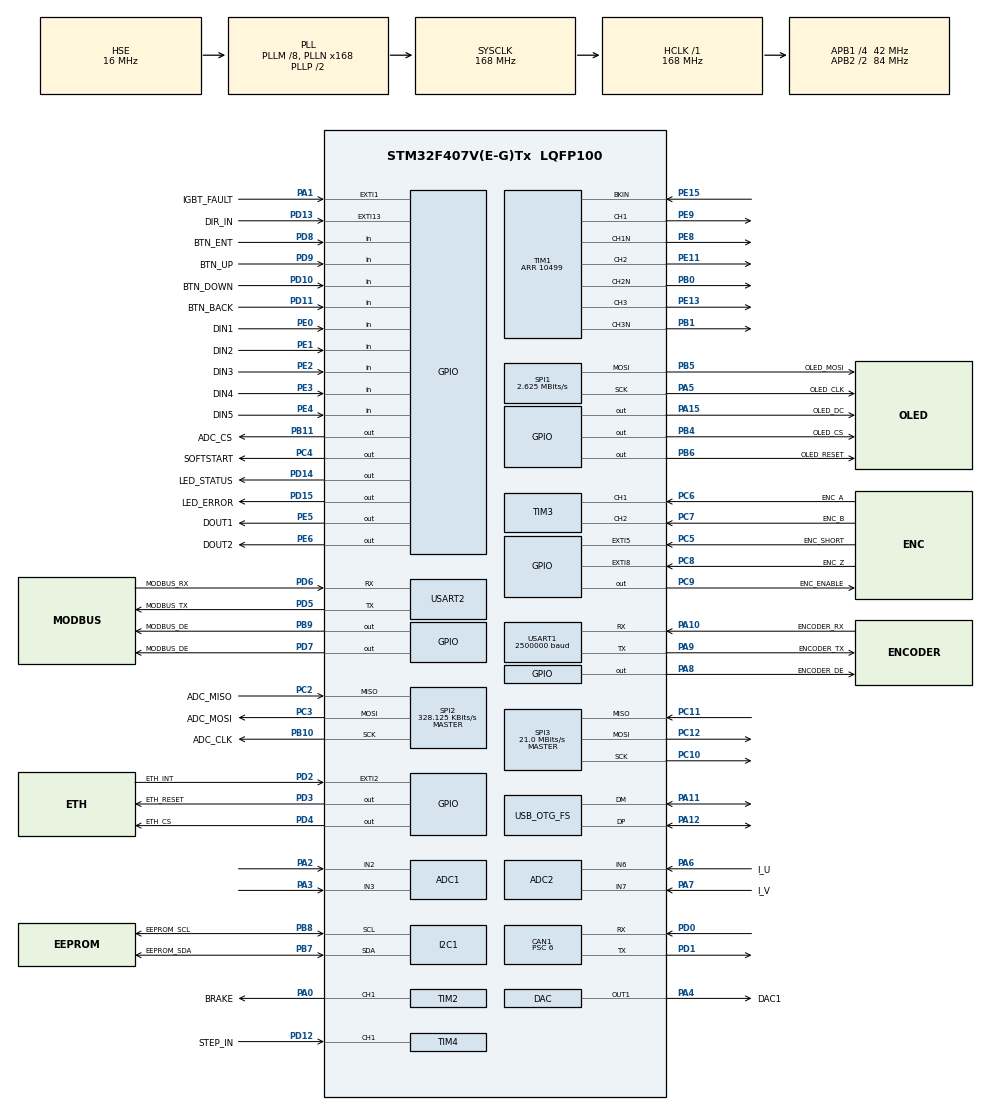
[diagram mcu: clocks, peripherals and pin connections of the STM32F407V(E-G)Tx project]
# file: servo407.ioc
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ADC1.Channel-1\#ChannelRegularConversion=ADC_CHANNEL_2
ADC1.Channel-2\#ChannelRegularConversion=ADC_CHANNEL_3
ADC1.ContinuousConvMode=ENABLE
ADC1.DMAContinuousRequests=ENABLE
ADC1.NbrOfConversion=2
ADC1.NbrOfConversionFlag=1
ADC1.Rank-1\#ChannelRegularConversion=1
ADC1.Rank-2\#ChannelRegularConversion=2
ADC1.SamplingTime-1\#ChannelRegularConversion=ADC_SAMPLETIME_56CYCLES
ADC1.SamplingTime-2\#ChannelRegularConversion=ADC_SAMPLETIME_56CYCLES
ADC1.ScanConvMode=ENABLE
ADC1.master=1
ADC2.Channel-2\#ChannelRegularConversion=ADC_CHANNEL_6
ADC2.Channel-3\#ChannelRegularConversion=ADC_CHANNEL_7
ADC2.ContinuousConvMode=ENABLE
ADC2.DMAContinuousRequests=ENABLE
ADC2.NbrOfConversion=2
ADC2.NbrOfConversionFlag=1
ADC2.Rank-2\#ChannelRegularConversion=1
ADC2.Rank-3\#ChannelRegularConversion=2
ADC2.SamplingTime-2\#ChannelRegularConversion=ADC_SAMPLETIME_15CYCLES
ADC2.SamplingTime-3\#ChannelRegularConversion=ADC_SAMPLETIME_15CYCLES
ADC2.ScanConvMode=ENABLE
CAN1.ABOM=ENABLE
CAN1.BS1=CAN_BS1_11TQ
CAN1.BS2=CAN_BS2_2TQ
CAN1.CalculateBaudRate=500000
CAN1.CalculateTimeBit=2000
CAN1.CalculateTimeQuantum=142.85714285714286
CAN1.NART=ENABLE
CAN1.Prescaler=6
Dma.ADC1.0.Direction=DMA_PERIPH_TO_MEMORY
Dma.ADC1.0.FIFOMode=DMA_FIFOMODE_DISABLE
Dma.ADC1.0.Instance=DMA2_Stream0
Dma.ADC1.0.MemDataAlignment=DMA_MDATAALIGN_HALFWORD
Dma.ADC1.0.MemInc=DMA_MINC_ENABLE
Dma.ADC1.0.Mode=DMA_CIRCULAR
Dma.ADC1.0.PeriphDataAlignment=DMA_PDATAALIGN_HALFWORD
Dma.ADC1.0.PeriphInc=DMA_PINC_DISABLE
Dma.ADC1.0.Priority=DMA_PRIORITY_LOW
Dma.ADC2.1.Direction=DMA_PERIPH_TO_MEMORY
Dma.ADC2.1.FIFOMode=DMA_FIFOMODE_DISABLE
Dma.ADC2.1.Instance=DMA2_Stream2
Dma.ADC2.1.MemDataAlignment=DMA_MDATAALIGN_HALFWORD
Dma.ADC2.1.MemInc=DMA_MINC_ENABLE
Dma.ADC2.1.Mode=DMA_CIRCULAR
Dma.ADC2.1.PeriphDataAlignment=DMA_PDATAALIGN_HALFWORD
Dma.ADC2.1.PeriphInc=DMA_PINC_DISABLE
Dma.ADC2.1.Priority=DMA_PRIORITY_LOW
Dma.I2C1_RX.7.Direction=DMA_PERIPH_TO_MEMORY
Dma.I2C1_RX.7.FIFOMode=DMA_FIFOMODE_DISABLE
Dma.I2C1_RX.7.Instance=DMA1_Stream0
Dma.I2C1_RX.7.MemDataAlignment=DMA_MDATAALIGN_BYTE
Dma.I2C1_RX.7.MemInc=DMA_MINC_ENABLE
Dma.I2C1_RX.7.Mode=DMA_NORMAL
Dma.I2C1_RX.7.PeriphDataAlignment=DMA_PDATAALIGN_BYTE
Dma.I2C1_RX.7.PeriphInc=DMA_PINC_DISABLE
Dma.I2C1_RX.7.Priority=DMA_PRIORITY_LOW
Dma.I2C1_TX.8.Direction=DMA_MEMORY_TO_PERIPH
Dma.I2C1_TX.8.FIFOMode=DMA_FIFOMODE_DISABLE
Dma.I2C1_TX.8.Instance=DMA1_Stream6
Dma.I2C1_TX.8.MemDataAlignment=DMA_MDATAALIGN_BYTE
Dma.I2C1_TX.8.MemInc=DMA_MINC_ENABLE
Dma.I2C1_TX.8.Mode=DMA_NORMAL
Dma.I2C1_TX.8.PeriphDataAlignment=DMA_PDATAALIGN_BYTE
Dma.I2C1_TX.8.PeriphInc=DMA_PINC_DISABLE
Dma.I2C1_TX.8.Priority=DMA_PRIORITY_LOW
Dma.Request0=ADC1
Dma.Request1=ADC2
Dma.Request2=SPI2_TX
Dma.Request3=SPI2_RX
Dma.Request4=USART1_RX
Dma.Request5=USART1_TX
Dma.Request6=SPI1_TX
Dma.Request7=I2C1_RX
Dma.Request8=I2C1_TX
Dma.SPI1_TX.6.Direction=DMA_MEMORY_TO_PERIPH
Dma.SPI1_TX.6.FIFOMode=DMA_FIFOMODE_DISABLE
Dma.SPI1_TX.6.Instance=DMA2_Stream3
Dma.SPI1_TX.6.MemDataAlignment=DMA_MDATAALIGN_BYTE
Dma.SPI1_TX.6.MemInc=DMA_MINC_ENABLE
Dma.SPI1_TX.6.Mode=DMA_NORMAL
Dma.SPI1_TX.6.PeriphDataAlignment=DMA_PDATAALIGN_BYTE
Dma.SPI1_TX.6.PeriphInc=DMA_PINC_DISABLE
Dma.SPI1_TX.6.Priority=DMA_PRIORITY_LOW
Dma.SPI2_RX.3.Direction=DMA_PERIPH_TO_MEMORY
Dma.SPI2_RX.3.FIFOMode=DMA_FIFOMODE_DISABLE
Dma.SPI2_RX.3.Instance=DMA1_Stream3
Dma.SPI2_RX.3.MemDataAlignment=DMA_MDATAALIGN_BYTE
Dma.SPI2_RX.3.MemInc=DMA_MINC_ENABLE
Dma.SPI2_RX.3.Mode=DMA_NORMAL
Dma.SPI2_RX.3.PeriphDataAlignment=DMA_PDATAALIGN_BYTE
Dma.SPI2_RX.3.PeriphInc=DMA_PINC_DISABLE
Dma.SPI2_RX.3.Priority=DMA_PRIORITY_LOW
Dma.SPI2_TX.2.Direction=DMA_MEMORY_TO_PERIPH
Dma.SPI2_TX.2.FIFOMode=DMA_FIFOMODE_DISABLE
Dma.SPI2_TX.2.Instance=DMA1_Stream4
Dma.SPI2_TX.2.MemDataAlignment=DMA_MDATAALIGN_BYTE
Dma.SPI2_TX.2.MemInc=DMA_MINC_ENABLE
Dma.SPI2_TX.2.Mode=DMA_NORMAL
Dma.SPI2_TX.2.PeriphDataAlignment=DMA_PDATAALIGN_BYTE
Dma.SPI2_TX.2.PeriphInc=DMA_PINC_DISABLE
Dma.SPI2_TX.2.Priority=DMA_PRIORITY_LOW
Dma.USART1_RX.4.Direction=DMA_PERIPH_TO_MEMORY
Dma.USART1_RX.4.FIFOMode=DMA_FIFOMODE_DISABLE
Dma.USART1_RX.4.Instance=DMA2_Stream5
Dma.USART1_RX.4.MemDataAlignment=DMA_MDATAALIGN_BYTE
Dma.USART1_RX.4.MemInc=DMA_MINC_ENABLE
Dma.USART1_RX.4.Mode=DMA_NORMAL
Dma.USART1_RX.4.PeriphDataAlignment=DMA_PDATAALIGN_BYTE
Dma.USART1_RX.4.PeriphInc=DMA_PINC_DISABLE
Dma.USART1_RX.4.Priority=DMA_PRIORITY_LOW
Dma.USART1_TX.5.Direction=DMA_MEMORY_TO_PERIPH
Dma.USART1_TX.5.FIFOMode=DMA_FIFOMODE_DISABLE
Dma.USART1_TX.5.Instance=DMA2_Stream7
Dma.USART1_TX.5.MemDataAlignment=DMA_MDATAALIGN_BYTE
Dma.USART1_TX.5.MemInc=DMA_MINC_ENABLE
Dma.USART1_TX.5.Mode=DMA_NORMAL
Dma.USART1_TX.5.PeriphDataAlignment=DMA_PDATAALIGN_BYTE
Dma.USART1_TX.5.PeriphInc=DMA_PINC_DISABLE
Dma.USART1_TX.5.Priority=DMA_PRIORITY_LOW
FREERTOS.Tasks01=defaultTask,32,256,StartDefaultTask,Default,NULL,Dynamic,NULL,NULL;taskModbusUSB,24,1024,StartTaskModbusUSB,Default,NULL,Dynamic,NULL,NULL;uiTask,16,1024,uiTaskStart,Default,NULL,Static,uiTaskBuffer,uiTaskControlBlock;canopen,25,2048,canopen_task,Default,NULL,Static,canopenBuffer,canopenControlBlock
FREERTOS.Timers01=timerSoftstart,timerSoftstartCallback,osTimerOnce,Default,NULL,Static,timerSoftstartControlBlock;LEDTimer,LEDTimerCallback,osTimerPeriodic,Default,NULL,Static,LEDTimerControlBlock
FREERTOS.configCHECK_FOR_STACK_OVERFLOW=2
FREERTOS.configENABLE_FPU=1
FREERTOS.configGENERATE_RUN_TIME_STATS=1
FREERTOS.configTIMER_TASK_PRIORITY=32
FREERTOS.configTOTAL_HEAP_SIZE=16384
FREERTOS.configUSE_MALLOC_FAILED_HOOK=1
FREERTOS.configUSE_NEWLIB_REENTRANT=1
I2C1.I2C_Mode=I2C_Fast
Mcu.Family=STM32F4
Mcu.Name=STM32F407V(E-G)Tx
Mcu.Package=LQFP100
NVIC.CAN1_RX0_IRQn=true\:7\:0\:true\:false\:true\:true\:true\:true\:true
NVIC.CAN1_RX1_IRQn=true\:7\:0\:true\:false\:true\:true\:true\:true\:true
NVIC.CAN1_TX_IRQn=true\:7\:0\:true\:false\:true\:true\:true\:true\:true
NVIC.DMA1_Stream0_IRQn=true\:7\:0\:true\:false\:true\:true\:false\:true\:true
NVIC.DMA1_Stream3_IRQn=true\:7\:0\:true\:false\:true\:true\:false\:true\:true
NVIC.DMA1_Stream4_IRQn=true\:7\:0\:true\:false\:true\:true\:false\:true\:true
NVIC.DMA1_Stream6_IRQn=true\:7\:0\:true\:false\:true\:true\:false\:true\:true
NVIC.DMA2_Stream0_IRQn=true\:7\:0\:true\:false\:true\:true\:false\:true\:true
NVIC.DMA2_Stream2_IRQn=true\:7\:0\:true\:false\:true\:true\:false\:true\:true
NVIC.DMA2_Stream3_IRQn=true\:7\:0\:true\:false\:true\:true\:false\:true\:true
NVIC.DMA2_Stream5_IRQn=true\:7\:0\:true\:false\:true\:true\:false\:true\:true
NVIC.DMA2_Stream7_IRQn=true\:7\:0\:true\:false\:true\:true\:false\:true\:true
NVIC.EXTI15_10_IRQn=true\:5\:0\:true\:false\:true\:true\:true\:true\:true
NVIC.EXTI1_IRQn=true\:5\:0\:true\:false\:true\:true\:true\:true\:true
NVIC.EXTI9_5_IRQn=true\:5\:0\:true\:false\:true\:true\:true\:true\:true
NVIC.OTG_FS_IRQn=true\:7\:0\:true\:false\:true\:true\:false\:true\:true
NVIC.PriorityGroup=NVIC_PRIORITYGROUP_4
NVIC.TIM1_TRG_COM_TIM11_IRQn=true\:15\:0\:false\:false\:true\:false\:false\:true\:true
NVIC.TIM5_IRQn=true\:6\:0\:true\:false\:true\:true\:true\:true\:true
NVIC.TIM6_DAC_IRQn=true\:7\:0\:true\:false\:true\:true\:true\:true\:true
NVIC.TIM7_IRQn=true\:5\:0\:false\:false\:true\:true\:true\:true\:true
NVIC.TimeBase=TIM1_TRG_COM_TIM11_IRQn
NVIC.TimeBaseIP=TIM11
PA0-WKUP.GPIO_Label=BRAKE
PA0-WKUP.Signal=S_TIM2_CH1_ETR
PA1.GPIO_Label=IGBT_FAULT
PA1.Signal=GPXTI1
PA10.GPIO_Label=ENCODER_RX
PA10.Mode=Asynchronous
PA10.Signal=USART1_RX
PA11.Mode=Device_Only
PA11.Signal=USB_OTG_FS_DM
PA12.Mode=Device_Only
PA12.Signal=USB_OTG_FS_DP
PA13.Mode=Trace_Asynchronous_SW
PA13.Signal=SYS_JTMS-SWDIO
PA14.Mode=Trace_Asynchronous_SW
PA14.Signal=SYS_JTCK-SWCLK
PA15.GPIO_Label=OLED_DC
PA15.Signal=GPIO_Output
PA2.Signal=ADCx_IN2
PA3.Signal=ADCx_IN3
PA4.GPIO_Label=DAC1
PA4.Signal=COMP_DAC1_group
PA5.GPIO_Label=OLED_CLK
PA5.Mode=TX_Only_Simplex_Unidirect_Master
PA5.Signal=SPI1_SCK
PA6.GPIO_Label=I_U
PA6.Signal=ADCx_IN6
PA7.GPIO_Label=I_V
PA7.Signal=ADCx_IN7
PA8.GPIO_Label=ENCODER_DE
PA8.PinState=GPIO_PIN_RESET
PA8.Signal=GPIO_Output
PA9.GPIO_Label=ENCODER_TX
PA9.Mode=Asynchronous
PA9.Signal=USART1_TX
PB0.GPIO_ModeDefaultPP=GPIO_MODE_AF_PP
PB0.GPIO_PuPd=GPIO_NOPULL
PB0.GPIO_Speed=GPIO_SPEED_FREQ_LOW
PB0.Mode=PWM Generation2 CH2 CH2N
PB0.Signal=TIM1_CH2N
PB1.GPIO_ModeDefaultPP=GPIO_MODE_AF_PP
PB1.GPIO_PuPd=GPIO_NOPULL
PB1.GPIO_Speed=GPIO_SPEED_FREQ_LOW
PB1.Mode=PWM Generation3 CH3 CH3N
PB1.Signal=TIM1_CH3N
PB10.GPIO_Label=ADC_CLK
PB10.Mode=Full_Duplex_Master
PB10.Signal=SPI2_SCK
PB11.GPIO_Label=ADC_CS
PB11.PinState=GPIO_PIN_SET
PB11.Signal=GPIO_Output
PB3.Mode=Trace_Asynchronous_SW
PB3.Signal=SYS_JTDO-SWO
PB4.GPIO_Label=OLED_CS
PB4.PinState=GPIO_PIN_SET
PB4.Signal=GPIO_Output
PB5.GPIO_Label=OLED_MOSI
PB5.Mode=TX_Only_Simplex_Unidirect_Master
PB5.Signal=SPI1_MOSI
PB6.GPIO_Label=OLED_RESET
PB6.PinState=GPIO_PIN_SET
PB6.Signal=GPIO_Output
PB7.GPIO_Label=EEPROM_SDA
PB7.Mode=I2C
PB7.Signal=I2C1_SDA
PB8.GPIO_Label=EEPROM_SCL
PB8.Mode=I2C
PB8.Signal=I2C1_SCL
PB9.GPIO_Label=MODBUS_DE
PB9.PinState=GPIO_PIN_SET
PB9.Signal=GPIO_Output
PC10.Mode=Full_Duplex_Master
PC10.Signal=SPI3_SCK
PC11.Mode=Full_Duplex_Master
PC11.Signal=SPI3_MISO
PC12.Mode=Full_Duplex_Master
PC12.Signal=SPI3_MOSI
PC2.GPIO_Label=ADC_MISO
PC2.Mode=Full_Duplex_Master
PC2.Signal=SPI2_MISO
PC3.GPIO_Label=ADC_MOSI
PC3.Mode=Full_Duplex_Master
PC3.Signal=SPI2_MOSI
PC4.GPIO_Label=SOFTSTART
PC4.Signal=GPIO_Output
PC5.GPIO_Label=ENC_SHORT
PC5.Signal=GPXTI5
PC6.GPIO_Label=ENC_A
PC6.Signal=S_TIM3_CH1
PC7.GPIO_Label=ENC_B
PC7.Signal=S_TIM3_CH2
PC8.GPIO_Label=ENC_Z
PC8.Signal=GPXTI8
PC9.GPIO_Label=ENC_ENABLE
PC9.Signal=GPIO_Output
PD0.Mode=CAN_Activate
PD0.Signal=CAN1_RX
PD1.Mode=CAN_Activate
PD1.Signal=CAN1_TX
PD10.GPIO_Label=BTN_DOWN
PD10.GPIO_PuPd=GPIO_PULLUP
PD10.Signal=GPIO_Input
PD11.GPIO_Label=BTN_BACK
PD11.GPIO_PuPd=GPIO_PULLUP
PD11.Signal=GPIO_Input
PD12.GPIO_Label=STEP_IN
PD12.Signal=S_TIM4_CH1
PD13.GPIO_Label=DIR_IN
PD13.GPIO_ModeDefaultEXTI=GPIO_MODE_IT_RISING_FALLING
PD13.Signal=GPXTI13
PD14.GPIO_Label=LED_STATUS
PD14.PinState=GPIO_PIN_SET
PD14.Signal=GPIO_Output
PD15.GPIO_Label=LED_ERROR
PD15.PinState=GPIO_PIN_SET
PD15.Signal=GPIO_Output
PD2.GPIO_Label=ETH_INT
PD2.Signal=GPXTI2
PD3.GPIO_Label=ETH_RESET
PD3.Signal=GPIO_Output
PD4.GPIO_Label=ETH_CS
PD4.PinState=GPIO_PIN_SET
PD4.Signal=GPIO_Output
PD5.GPIO_Label=MODBUS_TX
PD5.Mode=Asynchronous
PD5.Signal=USART2_TX
PD6.GPIO_Label=MODBUS_RX
PD6.Mode=Asynchronous
PD6.Signal=USART2_RX
PD7.GPIO_Label=MODBUS_DE
PD7.Signal=GPIO_Output
PD8.GPIO_Label=BTN_ENT
PD8.GPIO_PuPd=GPIO_PULLUP
PD8.Signal=GPIO_Input
PD9.GPIO_Label=BTN_UP
PD9.GPIO_PuPd=GPIO_PULLUP
PD9.Signal=GPIO_Input
PE0.GPIO_Label=DIN1
PE0.Signal=GPIO_Input
PE1.GPIO_Label=DIN2
PE1.Signal=GPIO_Input
PE11.GPIO_ModeDefaultPP=GPIO_MODE_AF_PP
PE11.GPIO_PuPd=GPIO_NOPULL
PE11.GPIO_Speed=GPIO_SPEED_FREQ_LOW
PE11.Signal=S_TIM1_CH2
PE13.GPIO_ModeDefaultPP=GPIO_MODE_AF_PP
PE13.GPIO_PuPd=GPIO_NOPULL
PE13.GPIO_Speed=GPIO_SPEED_FREQ_LOW
PE13.Signal=S_TIM1_CH3
PE15.Mode=Activate-Break-Input
PE15.Signal=TIM1_BKIN
PE2.GPIO_Label=DIN3
PE2.Signal=GPIO_Input
PE3.GPIO_Label=DIN4
PE3.Signal=GPIO_Input
PE4.GPIO_Label=DIN5
PE4.Signal=GPIO_Input
PE5.GPIO_Label=DOUT1
PE5.Signal=GPIO_Output
PE6.GPIO_Label=DOUT2
PE6.Signal=GPIO_Output
PE8.GPIO_ModeDefaultPP=GPIO_MODE_AF_PP
PE8.GPIO_PuPd=GPIO_NOPULL
PE8.GPIO_Speed=GPIO_SPEED_FREQ_LOW
PE8.Mode=PWM Generation1 CH1 CH1N
PE8.Signal=TIM1_CH1N
PE9.GPIO_ModeDefaultPP=GPIO_MODE_AF_PP
PE9.GPIO_PuPd=GPIO_NOPULL
PE9.GPIO_Speed=GPIO_SPEED_FREQ_LOW
PE9.Signal=S_TIM1_CH1
PH0-OSC_IN.Mode=HSE-External-Oscillator
PH0-OSC_IN.Signal=RCC_OSC_IN
PH1-OSC_OUT.Mode=HSE-External-Oscillator
PH1-OSC_OUT.Signal=RCC_OSC_OUT
ProjectManager.HeapSize=0x200
ProjectManager.StackSize=0x400
ProjectManager.TargetToolchain=STM32CubeIDE
RCC.48MHZClocksFreq_Value=48000000
RCC.AHBFreq_Value=168000000
RCC.APB1CLKDivider=RCC_HCLK_DIV4
RCC.APB1Freq_Value=42000000
RCC.APB1TimFreq_Value=84000000
RCC.APB2CLKDivider=RCC_HCLK_DIV2
RCC.APB2Freq_Value=84000000
RCC.APB2TimFreq_Value=168000000
RCC.CortexFreq_Value=168000000
RCC.HCLKFreq_Value=168000000
RCC.HSE_VALUE=16000000
RCC.HSI_VALUE=16000000
RCC.LSE_VALUE=32768
RCC.PLLM=8
RCC.PLLN=168
RCC.PLLQ=7
RCC.SYSCLKFreq_VALUE=168000000
RCC.SYSCLKSource=RCC_SYSCLKSOURCE_PLLCLK
RCC.VCOOutputFreq_Value=336000000
SH.ADCx_IN2.0=ADC1_IN2,IN2
SH.ADCx_IN3.0=ADC1_IN3,IN3
SH.ADCx_IN6.0=ADC1_IN6
SH.ADCx_IN6.1=ADC2_IN6,IN6
SH.ADCx_IN7.0=ADC1_IN7
SH.ADCx_IN7.1=ADC2_IN7,IN7
SH.COMP_DAC1_group.0=DAC_OUT1,DAC_OUT1
SH.S_TIM1_CH1.0=TIM1_CH1,PWM Generation1 CH1 CH1N
SH.S_TIM1_CH2.0=TIM1_CH2,PWM Generation2 CH2 CH2N
SH.S_TIM1_CH3.0=TIM1_CH3,PWM Generation3 CH3 CH3N
SH.S_TIM2_CH1_ETR.0=TIM2_CH1,PWM Generation1 CH1
SH.S_TIM3_CH1.0=TIM3_CH1,Encoder_Interface
SH.S_TIM3_CH2.0=TIM3_CH2,Encoder_Interface
SH.S_TIM4_CH1.0=TIM4_CH1,TriggerSource_TI1FP1
SPI1.BaudRatePrescaler=SPI_BAUDRATEPRESCALER_32
SPI1.CalculateBaudRate=2.625 MBits/s
SPI1.Direction=SPI_DIRECTION_2LINES
SPI1.Mode=SPI_MODE_MASTER
SPI1.VirtualType=VM_MASTER
SPI2.BaudRatePrescaler=SPI_BAUDRATEPRESCALER_128
SPI2.CalculateBaudRate=328.125 KBits/s
SPI2.Direction=SPI_DIRECTION_2LINES
SPI2.Mode=SPI_MODE_MASTER
SPI2.VirtualType=VM_MASTER
SPI3.CalculateBaudRate=21.0 MBits/s
SPI3.Direction=SPI_DIRECTION_2LINES
SPI3.Mode=SPI_MODE_MASTER
SPI3.VirtualType=VM_MASTER
TIM1.AutoReloadPreload=TIM_AUTORELOAD_PRELOAD_DISABLE
TIM1.BreakPolarity=TIM_BREAKPOLARITY_HIGH
TIM1.BreakState=TIM_BREAK_ENABLE
TIM1.Channel-PWM\ Generation1\ CH1\ CH1N=TIM_CHANNEL_1
TIM1.Channel-PWM\ Generation2\ CH2\ CH2N=TIM_CHANNEL_2
TIM1.Channel-PWM\ Generation3\ CH3\ CH3N=TIM_CHANNEL_3
TIM1.CounterMode=TIM_COUNTERMODE_CENTERALIGNED1
TIM1.DeadTime=90
TIM1.OC1Preload_PWM=DISABLE
TIM1.OC2Preload_PWM=DISABLE
TIM1.OC3Preload_PWM=DISABLE
TIM1.OCFastMode_PWM-PWM\ Generation1\ CH1\ CH1N=TIM_OCFAST_DISABLE
TIM1.OCFastMode_PWM-PWM\ Generation2\ CH2\ CH2N=TIM_OCFAST_DISABLE
TIM1.OCFastMode_PWM-PWM\ Generation3\ CH3\ CH3N=TIM_OCFAST_DISABLE
TIM1.OCMode_PWM-PWM\ Generation1\ CH1\ CH1N=TIM_OCMODE_PWM1
TIM1.OCMode_PWM-PWM\ Generation2\ CH2\ CH2N=TIM_OCMODE_PWM1
TIM1.OCMode_PWM-PWM\ Generation3\ CH3\ CH3N=TIM_OCMODE_PWM1
TIM1.OCNPolarity_1=TIM_OCNPOLARITY_HIGH
TIM1.OCNPolarity_2=TIM_OCNPOLARITY_HIGH
TIM1.OCNPolarity_3=TIM_OCNPOLARITY_HIGH
TIM1.OCPolarity_1=TIM_OCPOLARITY_HIGH
TIM1.OCPolarity_2=TIM_OCPOLARITY_HIGH
TIM1.OCPolarity_3=TIM_OCPOLARITY_HIGH
TIM1.Period=10499
TIM1.Pulse-PWM\ Generation1\ CH1\ CH1N=0
TIM1.Pulse-PWM\ Generation2\ CH2\ CH2N=0
TIM1.Pulse-PWM\ Generation3\ CH3\ CH3N=0
TIM2.Channel-PWM\ Generation1\ CH1=TIM_CHANNEL_1
TIM2.CounterMode=TIM_COUNTERMODE_CENTERALIGNED1
TIM2.OCFastMode_PWM-PWM\ Generation1\ CH1=TIM_OCFAST_ENABLE
TIM2.Period=10499
TIM3.IC1Filter=5
TIM3.IC2Filter=5
TIM4.Period=65535
TIM4.Slave_TriggerPolarity=TIM_TRIGGERPOLARITY_FALLING
TIM5.AutoReloadPreload=TIM_AUTORELOAD_PRELOAD_ENABLE
TIM5.Period=10499
TIM6.AutoReloadPreload=TIM_AUTORELOAD_PRELOAD_ENABLE
TIM6.Period=20999
TIM6.Prescaler=3
TIM7.AutoReloadPreload=TIM_AUTORELOAD_PRELOAD_ENABLE
TIM7.Period=10499
USART1.BaudRate=2500000
USART1.VirtualMode=VM_ASYNC
USART2.VirtualMode=VM_ASYNC
USB_DEVICE.CLASS_NAME_FS=CDC
USB_DEVICE.PRODUCT_STRING_CDC_FS=Servo2
USB_DEVICE.VirtualMode-CDC_FS=Cdc
USB_DEVICE.VirtualModeFS=Cdc_FS
USB_OTG_FS.VirtualMode=Device_Only
VP_ADC1_TempSens_Input.Mode=IN-TempSens
VP_FREERTOS_VS_CMSIS_V2.Mode=CMSIS_V2
VP_SYS_VS_tim11.Mode=TIM11
VP_TIM1_VS_ClockSourceINT.Mode=Internal
VP_TIM4_VS_ControllerModeClock.Mode=Clock Mode
VP_TIM5_VS_ClockSourceINT.Mode=Internal
VP_TIM6_VS_ClockSourceINT.Mode=Enable_Timer
VP_TIM7_VS_ClockSourceINT.Mode=Enable_Timer
VP_USB_DEVICE_VS_USB_DEVICE_CDC_FS.Mode=CDC_FS
board=custom

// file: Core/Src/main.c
/* USER CODE BEGIN Header */
/**
  ******************************************************************************
  * @file           : main.c
  * @brief          : Main program body
  ******************************************************************************
  * @attention
  *
  * Copyright (c) 2023 STMicroelectronics.
  * All rights reserved.
  *
  * This software is licensed under terms that can be found in the LICENSE file
  * in the root directory of this software component.
  * If no LICENSE file comes with this software, it is provided AS-IS.
  *
  ******************************************************************************
  */
/* USER CODE END Header */
#include "main.h"
#include "cmsis_os.h"
#include "usb_device.h"

/* USER CODE BEGIN Includes */
#include "inverter.h"
#include <math.h>
#include "comm_modbus.h"
#include "comm_canopen.h"
#include "user_interface.h"
#include "eeprom.h"
#include "CO_app_STM32.h"
/* USER CODE END Includes */

typedef StaticTask_t osStaticThreadDef_t;
typedef StaticTimer_t osStaticTimerDef_t;

/* USER CODE BEGIN PD */
/* Debug Exception and Monitor Control Register base address */
#define DEMCR                 *((volatile uint32_t*) 0xE000EDFCu)

/* ITM register addresses */
#define ITM_STIMULUS_PORT0    *((volatile uint32_t*) 0xE0000000u)
#define ITM_TRACE_EN          *((volatile uint32_t*) 0xE0000E00u)
/* USER CODE END PD */

ADC_HandleTypeDef hadc1;
ADC_HandleTypeDef hadc2;
DMA_HandleTypeDef hdma_adc1;
DMA_HandleTypeDef hdma_adc2;

CAN_HandleTypeDef hcan1;

DAC_HandleTypeDef hdac;

I2C_HandleTypeDef hi2c1;
DMA_HandleTypeDef hdma_i2c1_rx;
DMA_HandleTypeDef hdma_i2c1_tx;

SPI_HandleTypeDef hspi1;
SPI_HandleTypeDef hspi2;
SPI_HandleTypeDef hspi3;
DMA_HandleTypeDef hdma_spi1_tx;
DMA_HandleTypeDef hdma_spi2_tx;
DMA_HandleTypeDef hdma_spi2_rx;

TIM_HandleTypeDef htim1;
TIM_HandleTypeDef htim2;
TIM_HandleTypeDef htim3;
TIM_HandleTypeDef htim4;
TIM_HandleTypeDef htim5;
TIM_HandleTypeDef htim6;
TIM_HandleTypeDef htim7;

UART_HandleTypeDef huart1;
UART_HandleTypeDef huart2;
DMA_HandleTypeDef hdma_usart1_rx;
DMA_HandleTypeDef hdma_usart1_tx;

/* Definitions for defaultTask */
osThreadId_t defaultTaskHandle;
const osThreadAttr_t defaultTask_attributes = {
  .name = "defaultTask",
  .stack_size = 256 * 4,
  .priority = (osPriority_t) osPriorityAboveNormal,
};
/* Definitions for taskModbusUSB */
osThreadId_t taskModbusUSBHandle;
const osThreadAttr_t taskModbusUSB_attributes = {
  .name = "taskModbusUSB",
  .stack_size = 1024 * 4,
  .priority = (osPriority_t) osPriorityNormal,
};
/* Definitions for uiTask */
osThreadId_t uiTaskHandle;
uint32_t uiTaskBuffer[ 1024 ];
osStaticThreadDef_t uiTaskControlBlock;
const osThreadAttr_t uiTask_attributes = {
  .name = "uiTask",
  .cb_mem = &uiTaskControlBlock,
  .cb_size = sizeof(uiTaskControlBlock),
  .stack_mem = &uiTaskBuffer[0],
  .stack_size = sizeof(uiTaskBuffer),
  .priority = (osPriority_t) osPriorityBelowNormal,
};
/* Definitions for canopen */
osThreadId_t canopenHandle;
uint32_t canopenBuffer[ 2048 ];
osStaticThreadDef_t canopenControlBlock;
const osThreadAttr_t canopen_attributes = {
  .name = "canopen",
  .cb_mem = &canopenControlBlock,
  .cb_size = sizeof(canopenControlBlock),
  .stack_mem = &canopenBuffer[0],
  .stack_size = sizeof(canopenBuffer),
  .priority = (osPriority_t) osPriorityNormal1,
};
/* Definitions for timerSoftstart */
osTimerId_t timerSoftstartHandle;
osStaticTimerDef_t timerSoftstartControlBlock;
const osTimerAttr_t timerSoftstart_attributes = {
  .name = "timerSoftstart",
  .cb_mem = &timerSoftstartControlBlock,
  .cb_size = sizeof(timerSoftstartControlBlock),
};
/* Definitions for LEDTimer */
osTimerId_t LEDTimerHandle;
osStaticTimerDef_t LEDTimerControlBlock;
const osTimerAttr_t LEDTimer_attributes = {
  .name = "LEDTimer",
  .cb_mem = &LEDTimerControlBlock,
  .cb_size = sizeof(LEDTimerControlBlock),
};

void SystemClock_Config(void);
static void MX_GPIO_Init(void);
static void MX_DMA_Init(void);
static void MX_ADC1_Init(void);
static void MX_ADC2_Init(void);
static void MX_CAN1_Init(void);
static void MX_DAC_Init(void);
static void MX_SPI1_Init(void);
static void MX_SPI2_Init(void);
static void MX_TIM1_Init(void);
static void MX_TIM3_Init(void);
static void MX_TIM4_Init(void);
static void MX_USART1_UART_Init(void);
static void MX_USART2_UART_Init(void);
static void MX_I2C1_Init(void);
static void MX_SPI3_Init(void);
static void MX_TIM2_Init(void);
static void MX_TIM5_Init(void);
static void MX_TIM6_Init(void);
static void MX_TIM7_Init(void);
void StartDefaultTask(void *argument);
void StartTaskModbusUSB(void *argument);
void uiTaskStart(void *argument);
void canopen_task(void *argument);
void timerSoftstartCallback(void *argument);
void LEDTimerCallback(void *argument);

int main(void)
{

  /* MCU Configuration--------------------------------------------------------*/

  /* Reset of all peripherals, Initializes the Flash interface and the Systick. */
  HAL_Init();

  /* Configure the system clock */
  SystemClock_Config();

  /* USER CODE BEGIN SysInit */
  // Enable TRCENA
  DEMCR |= ( 1 << 24);
  // Enable stimulus port 0
  ITM_TRACE_EN |= ( 1 << 0);
  /* USER CODE END SysInit */

  /* Initialize all configured peripherals */
  MX_GPIO_Init();
  MX_DMA_Init();
  MX_ADC1_Init();
  MX_ADC2_Init();
  MX_CAN1_Init();
  MX_DAC_Init();
  MX_SPI1_Init();
  MX_SPI2_Init();
  MX_TIM1_Init();
  MX_TIM3_Init();
  MX_TIM4_Init();
  MX_USART1_UART_Init();
  MX_USART2_UART_Init();
  MX_I2C1_Init();
  MX_SPI3_Init();
  MX_TIM2_Init();
  MX_TIM5_Init();
  MX_TIM6_Init();
  MX_TIM7_Init();

  /* Init scheduler */
  osKernelInitialize();

  /* Create the timer(s) */
  /* creation of timerSoftstart */
  timerSoftstartHandle = osTimerNew(timerSoftstartCallback, osTimerOnce, NULL, &timerSoftstart_attributes);

  /* creation of LEDTimer */
  LEDTimerHandle = osTimerNew(LEDTimerCallback, osTimerPeriodic, NULL, &LEDTimer_attributes);

  /* Create the thread(s) */
  /* creation of defaultTask */
  defaultTaskHandle = osThreadNew(StartDefaultTask, NULL, &defaultTask_attributes);

  /* creation of taskModbusUSB */
  taskModbusUSBHandle = osThreadNew(StartTaskModbusUSB, NULL, &taskModbusUSB_attributes);

  /* creation of uiTask */
  uiTaskHandle = osThreadNew(uiTaskStart, NULL, &uiTask_attributes);

  /* creation of canopen */
  canopenHandle = osThreadNew(canopen_task, NULL, &canopen_attributes);

  /* USER CODE BEGIN RTOS_THREADS */
  /* adddefaultTaskHandle ... */
  /* USER CODE END RTOS_THREADS */

  /* Start scheduler */
  osKernelStart();
  /* We should never get here as control is now taken by the scheduler */
  /* Infinite loop */
  while (1)
  {

  }
}

void SystemClock_Config(void)
{
  RCC_OscInitTypeDef RCC_OscInitStruct = {0};
  RCC_ClkInitTypeDef RCC_ClkInitStruct = {0};

  /** Configure the main internal regulator output voltage
  */
  __HAL_RCC_PWR_CLK_ENABLE();
  __HAL_PWR_VOLTAGESCALING_CONFIG(PWR_REGULATOR_VOLTAGE_SCALE1);

  /** Initializes the RCC Oscillators according to the specified parameters
  * in the RCC_OscInitTypeDef structure.
  */
  RCC_OscInitStruct.OscillatorType = RCC_OSCILLATORTYPE_HSE;
  RCC_OscInitStruct.HSEState = RCC_HSE_ON;
  RCC_OscInitStruct.PLL.PLLState = RCC_PLL_ON;
  RCC_OscInitStruct.PLL.PLLSource = RCC_PLLSOURCE_HSE;
  RCC_OscInitStruct.PLL.PLLM = 8;
  RCC_OscInitStruct.PLL.PLLN = 168;
  RCC_OscInitStruct.PLL.PLLP = RCC_PLLP_DIV2;
  RCC_OscInitStruct.PLL.PLLQ = 7;
  if (HAL_RCC_OscConfig(&RCC_OscInitStruct) != HAL_OK)
  {
    Error_Handler();
  }

  /** Initializes the CPU, AHB and APB buses clocks
  */
  RCC_ClkInitStruct.ClockType = RCC_CLOCKTYPE_HCLK|RCC_CLOCKTYPE_SYSCLK
                              |RCC_CLOCKTYPE_PCLK1|RCC_CLOCKTYPE_PCLK2;
  RCC_ClkInitStruct.SYSCLKSource = RCC_SYSCLKSOURCE_PLLCLK;
  RCC_ClkInitStruct.AHBCLKDivider = RCC_SYSCLK_DIV1;
  RCC_ClkInitStruct.APB1CLKDivider = RCC_HCLK_DIV4;
  RCC_ClkInitStruct.APB2CLKDivider = RCC_HCLK_DIV2;

  if (HAL_RCC_ClockConfig(&RCC_ClkInitStruct, FLASH_LATENCY_5) != HAL_OK)
  {
    Error_Handler();
  }
}

static void MX_ADC1_Init(void)
{

  ADC_ChannelConfTypeDef sConfig = {0};

  /** Configure the global features of the ADC (Clock, Resolution, Data Alignment and number of conversion)
  */
  hadc1.Instance = ADC1;
  hadc1.Init.ClockPrescaler = ADC_CLOCK_SYNC_PCLK_DIV4;
  hadc1.Init.Resolution = ADC_RESOLUTION_12B;
  hadc1.Init.ScanConvMode = ENABLE;
  hadc1.Init.ContinuousConvMode = ENABLE;
  hadc1.Init.DiscontinuousConvMode = DISABLE;
  hadc1.Init.ExternalTrigConvEdge = ADC_EXTERNALTRIGCONVEDGE_NONE;
  hadc1.Init.ExternalTrigConv = ADC_SOFTWARE_START;
  hadc1.Init.DataAlign = ADC_DATAALIGN_RIGHT;
  hadc1.Init.NbrOfConversion = 2;
  hadc1.Init.DMAContinuousRequests = ENABLE;
  hadc1.Init.EOCSelection = ADC_EOC_SINGLE_CONV;
  if (HAL_ADC_Init(&hadc1) != HAL_OK)
  {
    Error_Handler();
  }

  /** Configure for the selected ADC regular channel its corresponding rank in the sequencer and its sample time.
  */
  sConfig.Channel = ADC_CHANNEL_2;
  sConfig.Rank = 1;
  sConfig.SamplingTime = ADC_SAMPLETIME_56CYCLES;
  if (HAL_ADC_ConfigChannel(&hadc1, &sConfig) != HAL_OK)
  {
    Error_Handler();
  }

  /** Configure for the selected ADC regular channel its corresponding rank in the sequencer and its sample time.
  */
  sConfig.Channel = ADC_CHANNEL_3;
  sConfig.Rank = 2;
  if (HAL_ADC_ConfigChannel(&hadc1, &sConfig) != HAL_OK)
  {
    Error_Handler();
  }

}

static void MX_ADC2_Init(void)
{

  ADC_ChannelConfTypeDef sConfig = {0};

  /** Configure the global features of the ADC (Clock, Resolution, Data Alignment and number of conversion)
  */
  hadc2.Instance = ADC2;
  hadc2.Init.ClockPrescaler = ADC_CLOCK_SYNC_PCLK_DIV4;
  hadc2.Init.Resolution = ADC_RESOLUTION_12B;
  hadc2.Init.ScanConvMode = ENABLE;
  hadc2.Init.ContinuousConvMode = ENABLE;
  hadc2.Init.DiscontinuousConvMode = DISABLE;
  hadc2.Init.ExternalTrigConvEdge = ADC_EXTERNALTRIGCONVEDGE_NONE;
  hadc2.Init.ExternalTrigConv = ADC_SOFTWARE_START;
  hadc2.Init.DataAlign = ADC_DATAALIGN_RIGHT;
  hadc2.Init.NbrOfConversion = 2;
  hadc2.Init.DMAContinuousRequests = ENABLE;
  hadc2.Init.EOCSelection = ADC_EOC_SINGLE_CONV;
  if (HAL_ADC_Init(&hadc2) != HAL_OK)
  {
    Error_Handler();
  }

  /** Configure for the selected ADC regular channel its corresponding rank in the sequencer and its sample time.
  */
  sConfig.Channel = ADC_CHANNEL_6;
  sConfig.Rank = 1;
  sConfig.SamplingTime = ADC_SAMPLETIME_15CYCLES;
  if (HAL_ADC_ConfigChannel(&hadc2, &sConfig) != HAL_OK)
  {
    Error_Handler();
  }

  /** Configure for the selected ADC regular channel its corresponding rank in the sequencer and its sample time.
  */
  sConfig.Channel = ADC_CHANNEL_7;
  sConfig.Rank = 2;
  if (HAL_ADC_ConfigChannel(&hadc2, &sConfig) != HAL_OK)
  {
    Error_Handler();
  }

}

static void MX_CAN1_Init(void)
{

  hcan1.Instance = CAN1;
  hcan1.Init.Prescaler = 6;
  hcan1.Init.Mode = CAN_MODE_NORMAL;
  hcan1.Init.SyncJumpWidth = CAN_SJW_1TQ;
  hcan1.Init.TimeSeg1 = CAN_BS1_11TQ;
  hcan1.Init.TimeSeg2 = CAN_BS2_2TQ;
  hcan1.Init.TimeTriggeredMode = DISABLE;
  hcan1.Init.AutoBusOff = ENABLE;
  hcan1.Init.AutoWakeUp = DISABLE;
  hcan1.Init.AutoRetransmission = ENABLE;
  hcan1.Init.ReceiveFifoLocked = DISABLE;
  hcan1.Init.TransmitFifoPriority = DISABLE;
  if (HAL_CAN_Init(&hcan1) != HAL_OK)
  {
    Error_Handler();
  }

}

static void MX_DAC_Init(void)
{

  DAC_ChannelConfTypeDef sConfig = {0};

  /** DAC Initialization
  */
  hdac.Instance = DAC;
  if (HAL_DAC_Init(&hdac) != HAL_OK)
  {
    Error_Handler();
  }

  /** DAC channel OUT1 config
  */
  sConfig.DAC_Trigger = DAC_TRIGGER_NONE;
  sConfig.DAC_OutputBuffer = DAC_OUTPUTBUFFER_ENABLE;
  if (HAL_DAC_ConfigChannel(&hdac, &sConfig, DAC_CHANNEL_1) != HAL_OK)
  {
    Error_Handler();
  }

}

static void MX_I2C1_Init(void)
{

  hi2c1.Instance = I2C1;
  hi2c1.Init.ClockSpeed = 400000;
  hi2c1.Init.DutyCycle = I2C_DUTYCYCLE_2;
  hi2c1.Init.OwnAddress1 = 0;
  hi2c1.Init.AddressingMode = I2C_ADDRESSINGMODE_7BIT;
  hi2c1.Init.DualAddressMode = I2C_DUALADDRESS_DISABLE;
  hi2c1.Init.OwnAddress2 = 0;
  hi2c1.Init.GeneralCallMode = I2C_GENERALCALL_DISABLE;
  hi2c1.Init.NoStretchMode = I2C_NOSTRETCH_DISABLE;
  if (HAL_I2C_Init(&hi2c1) != HAL_OK)
  {
    Error_Handler();
  }

}

static void MX_SPI1_Init(void)
{

  /* SPI1 parameter configuration*/
  hspi1.Instance = SPI1;
  hspi1.Init.Mode = SPI_MODE_MASTER;
  hspi1.Init.Direction = SPI_DIRECTION_2LINES;
  hspi1.Init.DataSize = SPI_DATASIZE_8BIT;
  hspi1.Init.CLKPolarity = SPI_POLARITY_LOW;
  hspi1.Init.CLKPhase = SPI_PHASE_1EDGE;
  hspi1.Init.NSS = SPI_NSS_SOFT;
  hspi1.Init.BaudRatePrescaler = SPI_BAUDRATEPRESCALER_32;
  hspi1.Init.FirstBit = SPI_FIRSTBIT_MSB;
  hspi1.Init.TIMode = SPI_TIMODE_DISABLE;
  hspi1.Init.CRCCalculation = SPI_CRCCALCULATION_DISABLE;
  hspi1.Init.CRCPolynomial = 10;
  if (HAL_SPI_Init(&hspi1) != HAL_OK)
  {
    Error_Handler();
  }

}

static void MX_SPI2_Init(void)
{

  /* SPI2 parameter configuration*/
  hspi2.Instance = SPI2;
  hspi2.Init.Mode = SPI_MODE_MASTER;
  hspi2.Init.Direction = SPI_DIRECTION_2LINES;
  hspi2.Init.DataSize = SPI_DATASIZE_8BIT;
  hspi2.Init.CLKPolarity = SPI_POLARITY_LOW;
  hspi2.Init.CLKPhase = SPI_PHASE_1EDGE;
  hspi2.Init.NSS = SPI_NSS_SOFT;
  hspi2.Init.BaudRatePrescaler = SPI_BAUDRATEPRESCALER_128;
  hspi2.Init.FirstBit = SPI_FIRSTBIT_MSB;
  hspi2.Init.TIMode = SPI_TIMODE_DISABLE;
  hspi2.Init.CRCCalculation = SPI_CRCCALCULATION_DISABLE;
  hspi2.Init.CRCPolynomial = 10;
  if (HAL_SPI_Init(&hspi2) != HAL_OK)
  {
    Error_Handler();
  }

}

static void MX_SPI3_Init(void)
{

  /* SPI3 parameter configuration*/
  hspi3.Instance = SPI3;
  hspi3.Init.Mode = SPI_MODE_MASTER;
  hspi3.Init.Direction = SPI_DIRECTION_2LINES;
  hspi3.Init.DataSize = SPI_DATASIZE_8BIT;
  hspi3.Init.CLKPolarity = SPI_POLARITY_LOW;
  hspi3.Init.CLKPhase = SPI_PHASE_1EDGE;
  hspi3.Init.NSS = SPI_NSS_SOFT;
  hspi3.Init.BaudRatePrescaler = SPI_BAUDRATEPRESCALER_2;
  hspi3.Init.FirstBit = SPI_FIRSTBIT_MSB;
  hspi3.Init.TIMode = SPI_TIMODE_DISABLE;
  hspi3.Init.CRCCalculation = SPI_CRCCALCULATION_DISABLE;
  hspi3.Init.CRCPolynomial = 10;
  if (HAL_SPI_Init(&hspi3) != HAL_OK)
  {
    Error_Handler();
  }

}

static void MX_TIM1_Init(void)
{

  TIM_ClockConfigTypeDef sClockSourceConfig = {0};
  TIM_MasterConfigTypeDef sMasterConfig = {0};
  TIM_OC_InitTypeDef sConfigOC = {0};
  TIM_BreakDeadTimeConfigTypeDef sBreakDeadTimeConfig = {0};

  htim1.Instance = TIM1;
  htim1.Init.Prescaler = 0;
  htim1.Init.CounterMode = TIM_COUNTERMODE_CENTERALIGNED1;
  htim1.Init.Period = 10499;
  htim1.Init.ClockDivision = TIM_CLOCKDIVISION_DIV1;
  htim1.Init.RepetitionCounter = 0;
  htim1.Init.AutoReloadPreload = TIM_AUTORELOAD_PRELOAD_DISABLE;
  if (HAL_TIM_Base_Init(&htim1) != HAL_OK)
  {
    Error_Handler();
  }
  sClockSourceConfig.ClockSource = TIM_CLOCKSOURCE_INTERNAL;
  if (HAL_TIM_ConfigClockSource(&htim1, &sClockSourceConfig) != HAL_OK)
  {
    Error_Handler();
  }
  if (HAL_TIM_PWM_Init(&htim1) != HAL_OK)
  {
    Error_Handler();
  }
  sMasterConfig.MasterOutputTrigger = TIM_TRGO_RESET;
  sMasterConfig.MasterSlaveMode = TIM_MASTERSLAVEMODE_DISABLE;
  if (HAL_TIMEx_MasterConfigSynchronization(&htim1, &sMasterConfig) != HAL_OK)
  {
    Error_Handler();
  }
  sConfigOC.OCMode = TIM_OCMODE_PWM1;
  sConfigOC.Pulse = 0;
  sConfigOC.OCPolarity = TIM_OCPOLARITY_HIGH;
  sConfigOC.OCNPolarity = TIM_OCNPOLARITY_HIGH;
  sConfigOC.OCFastMode = TIM_OCFAST_DISABLE;
  sConfigOC.OCIdleState = TIM_OCIDLESTATE_RESET;
  sConfigOC.OCNIdleState = TIM_OCNIDLESTATE_RESET;
  if (HAL_TIM_PWM_ConfigChannel(&htim1, &sConfigOC, TIM_CHANNEL_1) != HAL_OK)
  {
    Error_Handler();
  }
  __HAL_TIM_DISABLE_OCxPRELOAD(&htim1, TIM_CHANNEL_1);
  if (HAL_TIM_PWM_ConfigChannel(&htim1, &sConfigOC, TIM_CHANNEL_2) != HAL_OK)
  {
    Error_Handler();
  }
  __HAL_TIM_DISABLE_OCxPRELOAD(&htim1, TIM_CHANNEL_2);
  if (HAL_TIM_PWM_ConfigChannel(&htim1, &sConfigOC, TIM_CHANNEL_3) != HAL_OK)
  {
    Error_Handler();
  }
  __HAL_TIM_DISABLE_OCxPRELOAD(&htim1, TIM_CHANNEL_3);
  sBreakDeadTimeConfig.OffStateRunMode = TIM_OSSR_DISABLE;
  sBreakDeadTimeConfig.OffStateIDLEMode = TIM_OSSI_DISABLE;
  sBreakDeadTimeConfig.LockLevel = TIM_LOCKLEVEL_OFF;
  sBreakDeadTimeConfig.DeadTime = 90;
  sBreakDeadTimeConfig.BreakState = TIM_BREAK_ENABLE;
  sBreakDeadTimeConfig.BreakPolarity = TIM_BREAKPOLARITY_HIGH;
  sBreakDeadTimeConfig.AutomaticOutput = TIM_AUTOMATICOUTPUT_DISABLE;
  if (HAL_TIMEx_ConfigBreakDeadTime(&htim1, &sBreakDeadTimeConfig) != HAL_OK)
  {
    Error_Handler();
  }
  HAL_TIM_MspPostInit(&htim1);

}

static void MX_TIM2_Init(void)
{

  TIM_MasterConfigTypeDef sMasterConfig = {0};
  TIM_OC_InitTypeDef sConfigOC = {0};

  htim2.Instance = TIM2;
  htim2.Init.Prescaler = 0;
  htim2.Init.CounterMode = TIM_COUNTERMODE_CENTERALIGNED1;
  htim2.Init.Period = 10499;
  htim2.Init.ClockDivision = TIM_CLOCKDIVISION_DIV1;
  htim2.Init.AutoReloadPreload = TIM_AUTORELOAD_PRELOAD_DISABLE;
  if (HAL_TIM_PWM_Init(&htim2) != HAL_OK)
  {
    Error_Handler();
  }
  sMasterConfig.MasterOutputTrigger = TIM_TRGO_RESET;
  sMasterConfig.MasterSlaveMode = TIM_MASTERSLAVEMODE_DISABLE;
  if (HAL_TIMEx_MasterConfigSynchronization(&htim2, &sMasterConfig) != HAL_OK)
  {
    Error_Handler();
  }
  sConfigOC.OCMode = TIM_OCMODE_PWM1;
  sConfigOC.Pulse = 0;
  sConfigOC.OCPolarity = TIM_OCPOLARITY_HIGH;
  sConfigOC.OCFastMode = TIM_OCFAST_ENABLE;
  if (HAL_TIM_PWM_ConfigChannel(&htim2, &sConfigOC, TIM_CHANNEL_1) != HAL_OK)
  {
    Error_Handler();
  }
  HAL_TIM_MspPostInit(&htim2);

}

static void MX_TIM3_Init(void)
{

  TIM_Encoder_InitTypeDef sConfig = {0};
  TIM_MasterConfigTypeDef sMasterConfig = {0};

  htim3.Instance = TIM3;
  htim3.Init.Prescaler = 0;
  htim3.Init.CounterMode = TIM_COUNTERMODE_UP;
  htim3.Init.Period = 65535;
  htim3.Init.ClockDivision = TIM_CLOCKDIVISION_DIV1;
  htim3.Init.AutoReloadPreload = TIM_AUTORELOAD_PRELOAD_DISABLE;
  sConfig.EncoderMode = TIM_ENCODERMODE_TI1;
  sConfig.IC1Polarity = TIM_ICPOLARITY_RISING;
  sConfig.IC1Selection = TIM_ICSELECTION_DIRECTTI;
  sConfig.IC1Prescaler = TIM_ICPSC_DIV1;
  sConfig.IC1Filter = 5;
  sConfig.IC2Polarity = TIM_ICPOLARITY_RISING;
  sConfig.IC2Selection = TIM_ICSELECTION_DIRECTTI;
  sConfig.IC2Prescaler = TIM_ICPSC_DIV1;
  sConfig.IC2Filter = 5;
  if (HAL_TIM_Encoder_Init(&htim3, &sConfig) != HAL_OK)
  {
    Error_Handler();
  }
  sMasterConfig.MasterOutputTrigger = TIM_TRGO_RESET;
  sMasterConfig.MasterSlaveMode = TIM_MASTERSLAVEMODE_DISABLE;
  if (HAL_TIMEx_MasterConfigSynchronization(&htim3, &sMasterConfig) != HAL_OK)
  {
    Error_Handler();
  }

}

static void MX_TIM4_Init(void)
{

  TIM_SlaveConfigTypeDef sSlaveConfig = {0};
  TIM_MasterConfigTypeDef sMasterConfig = {0};

  htim4.Instance = TIM4;
  htim4.Init.Prescaler = 0;
  htim4.Init.CounterMode = TIM_COUNTERMODE_UP;
  htim4.Init.Period = 65535;
  htim4.Init.ClockDivision = TIM_CLOCKDIVISION_DIV1;
  htim4.Init.AutoReloadPreload = TIM_AUTORELOAD_PRELOAD_DISABLE;
  if (HAL_TIM_Base_Init(&htim4) != HAL_OK)
  {
    Error_Handler();
  }
  sSlaveConfig.SlaveMode = TIM_SLAVEMODE_EXTERNAL1;
  sSlaveConfig.InputTrigger = TIM_TS_TI1FP1;
  sSlaveConfig.TriggerPolarity = TIM_TRIGGERPOLARITY_FALLING;
  sSlaveConfig.TriggerFilter = 0;
  if (HAL_TIM_SlaveConfigSynchro(&htim4, &sSlaveConfig) != HAL_OK)
  {
    Error_Handler();
  }
  sMasterConfig.MasterOutputTrigger = TIM_TRGO_RESET;
  sMasterConfig.MasterSlaveMode = TIM_MASTERSLAVEMODE_DISABLE;
  if (HAL_TIMEx_MasterConfigSynchronization(&htim4, &sMasterConfig) != HAL_OK)
  {
    Error_Handler();
  }

}

static void MX_TIM5_Init(void)
{

  TIM_ClockConfigTypeDef sClockSourceConfig = {0};
  TIM_MasterConfigTypeDef sMasterConfig = {0};

  htim5.Instance = TIM5;
  htim5.Init.Prescaler = 0;
  htim5.Init.CounterMode = TIM_COUNTERMODE_UP;
  htim5.Init.Period = 10499;
  htim5.Init.ClockDivision = TIM_CLOCKDIVISION_DIV1;
  htim5.Init.AutoReloadPreload = TIM_AUTORELOAD_PRELOAD_ENABLE;
  if (HAL_TIM_Base_Init(&htim5) != HAL_OK)
  {
    Error_Handler();
  }
  sClockSourceConfig.ClockSource = TIM_CLOCKSOURCE_INTERNAL;
  if (HAL_TIM_ConfigClockSource(&htim5, &sClockSourceConfig) != HAL_OK)
  {
    Error_Handler();
  }
  sMasterConfig.MasterOutputTrigger = TIM_TRGO_RESET;
  sMasterConfig.MasterSlaveMode = TIM_MASTERSLAVEMODE_DISABLE;
  if (HAL_TIMEx_MasterConfigSynchronization(&htim5, &sMasterConfig) != HAL_OK)
  {
    Error_Handler();
  }

}

static void MX_TIM6_Init(void)
{

  TIM_MasterConfigTypeDef sMasterConfig = {0};

  htim6.Instance = TIM6;
  htim6.Init.Prescaler = 3;
  htim6.Init.CounterMode = TIM_COUNTERMODE_UP;
  htim6.Init.Period = 20999;
  htim6.Init.AutoReloadPreload = TIM_AUTORELOAD_PRELOAD_ENABLE;
  if (HAL_TIM_Base_Init(&htim6) != HAL_OK)
  {
    Error_Handler();
  }
  sMasterConfig.MasterOutputTrigger = TIM_TRGO_RESET;
  sMasterConfig.MasterSlaveMode = TIM_MASTERSLAVEMODE_DISABLE;
  if (HAL_TIMEx_MasterConfigSynchronization(&htim6, &sMasterConfig) != HAL_OK)
  {
    Error_Handler();
  }

}

static void MX_TIM7_Init(void)
{

  TIM_MasterConfigTypeDef sMasterConfig = {0};

  htim7.Instance = TIM7;
  htim7.Init.Prescaler = 0;
  htim7.Init.CounterMode = TIM_COUNTERMODE_UP;
  htim7.Init.Period = 10499;
  htim7.Init.AutoReloadPreload = TIM_AUTORELOAD_PRELOAD_ENABLE;
  if (HAL_TIM_Base_Init(&htim7) != HAL_OK)
  {
    Error_Handler();
  }
  sMasterConfig.MasterOutputTrigger = TIM_TRGO_RESET;
  sMasterConfig.MasterSlaveMode = TIM_MASTERSLAVEMODE_DISABLE;
  if (HAL_TIMEx_MasterConfigSynchronization(&htim7, &sMasterConfig) != HAL_OK)
  {
    Error_Handler();
  }

}

static void MX_USART1_UART_Init(void)
{

  huart1.Instance = USART1;
  huart1.Init.BaudRate = 2500000;
  huart1.Init.WordLength = UART_WORDLENGTH_8B;
  huart1.Init.StopBits = UART_STOPBITS_1;
  huart1.Init.Parity = UART_PARITY_NONE;
  huart1.Init.Mode = UART_MODE_TX_RX;
  huart1.Init.HwFlowCtl = UART_HWCONTROL_NONE;
  huart1.Init.OverSampling = UART_OVERSAMPLING_16;
  if (HAL_UART_Init(&huart1) != HAL_OK)
  {
    Error_Handler();
  }

}

static void MX_USART2_UART_Init(void)
{

  huart2.Instance = USART2;
  huart2.Init.BaudRate = 115200;
  huart2.Init.WordLength = UART_WORDLENGTH_8B;
  huart2.Init.StopBits = UART_STOPBITS_1;
  huart2.Init.Parity = UART_PARITY_NONE;
  huart2.Init.Mode = UART_MODE_TX_RX;
  huart2.Init.HwFlowCtl = UART_HWCONTROL_NONE;
  huart2.Init.OverSampling = UART_OVERSAMPLING_16;
  if (HAL_UART_Init(&huart2) != HAL_OK)
  {
    Error_Handler();
  }

}

static void MX_DMA_Init(void)
{

  /* DMA controller clock enable */
  __HAL_RCC_DMA2_CLK_ENABLE();
  __HAL_RCC_DMA1_CLK_ENABLE();

  /* DMA interrupt init */
  /* DMA1_Stream0_IRQn interrupt configuration */
  HAL_NVIC_SetPriority(DMA1_Stream0_IRQn, 7, 0);
  HAL_NVIC_EnableIRQ(DMA1_Stream0_IRQn);
  /* DMA1_Stream3_IRQn interrupt configuration */
  HAL_NVIC_SetPriority(DMA1_Stream3_IRQn, 7, 0);
  HAL_NVIC_EnableIRQ(DMA1_Stream3_IRQn);
  /* DMA1_Stream4_IRQn interrupt configuration */
  HAL_NVIC_SetPriority(DMA1_Stream4_IRQn, 7, 0);
  HAL_NVIC_EnableIRQ(DMA1_Stream4_IRQn);
  /* DMA1_Stream6_IRQn interrupt configuration */
  HAL_NVIC_SetPriority(DMA1_Stream6_IRQn, 7, 0);
  HAL_NVIC_EnableIRQ(DMA1_Stream6_IRQn);
  /* DMA2_Stream0_IRQn interrupt configuration */
  HAL_NVIC_SetPriority(DMA2_Stream0_IRQn, 7, 0);
  HAL_NVIC_EnableIRQ(DMA2_Stream0_IRQn);
  /* DMA2_Stream2_IRQn interrupt configuration */
  HAL_NVIC_SetPriority(DMA2_Stream2_IRQn, 7, 0);
  HAL_NVIC_EnableIRQ(DMA2_Stream2_IRQn);
  /* DMA2_Stream3_IRQn interrupt configuration */
  HAL_NVIC_SetPriority(DMA2_Stream3_IRQn, 7, 0);
  HAL_NVIC_EnableIRQ(DMA2_Stream3_IRQn);
  /* DMA2_Stream5_IRQn interrupt configuration */
  HAL_NVIC_SetPriority(DMA2_Stream5_IRQn, 7, 0);
  HAL_NVIC_EnableIRQ(DMA2_Stream5_IRQn);
  /* DMA2_Stream7_IRQn interrupt configuration */
  HAL_NVIC_SetPriority(DMA2_Stream7_IRQn, 7, 0);
  HAL_NVIC_EnableIRQ(DMA2_Stream7_IRQn);

}

static void MX_GPIO_Init(void)
{
  GPIO_InitTypeDef GPIO_InitStruct = {0};

  /* GPIO Ports Clock Enable */
  __HAL_RCC_GPIOE_CLK_ENABLE();
  __HAL_RCC_GPIOH_CLK_ENABLE();
  __HAL_RCC_GPIOC_CLK_ENABLE();
  __HAL_RCC_GPIOA_CLK_ENABLE();
  __HAL_RCC_GPIOB_CLK_ENABLE();
  __HAL_RCC_GPIOD_CLK_ENABLE();

  /*Configure GPIO pin Output Level */
  HAL_GPIO_WritePin(GPIOE, DOUT1_Pin|DOUT2_Pin, GPIO_PIN_RESET);

  /*Configure GPIO pin Output Level */
  HAL_GPIO_WritePin(GPIOC, SOFTSTART_Pin|ENC_ENABLE_Pin, GPIO_PIN_RESET);

  /*Configure GPIO pin Output Level */
  HAL_GPIO_WritePin(GPIOB, ADC_CS_Pin|OLED_CS_Pin|OLED_RESET_Pin|MODBUS_DEB9_Pin, GPIO_PIN_SET);

  /*Configure GPIO pin Output Level */
  HAL_GPIO_WritePin(GPIOD, LED_STATUS_Pin|LED_ERROR_Pin|ETH_CS_Pin, GPIO_PIN_SET);

  /*Configure GPIO pin Output Level */
  HAL_GPIO_WritePin(GPIOA, ENCODER_DE_Pin|OLED_DC_Pin, GPIO_PIN_RESET);

  /*Configure GPIO pin Output Level */
  HAL_GPIO_WritePin(GPIOD, ETH_RESET_Pin|MODBUS_DE_Pin, GPIO_PIN_RESET);

  /*Configure GPIO pins : DIN3_Pin DIN4_Pin DIN5_Pin DIN1_Pin
                           DIN2_Pin */
  GPIO_InitStruct.Pin = DIN3_Pin|DIN4_Pin|DIN5_Pin|DIN1_Pin
                          |DIN2_Pin;
  GPIO_InitStruct.Mode = GPIO_MODE_INPUT;
  GPIO_InitStruct.Pull = GPIO_NOPULL;
  HAL_GPIO_Init(GPIOE, &GPIO_InitStruct);

  /*Configure GPIO pins : DOUT1_Pin DOUT2_Pin */
  GPIO_InitStruct.Pin = DOUT1_Pin|DOUT2_Pin;
  GPIO_InitStruct.Mode = GPIO_MODE_OUTPUT_PP;
  GPIO_InitStruct.Pull = GPIO_NOPULL;
  GPIO_InitStruct.Speed = GPIO_SPEED_FREQ_LOW;
  HAL_GPIO_Init(GPIOE, &GPIO_InitStruct);

  /*Configure GPIO pin : IGBT_FAULT_Pin */
  GPIO_InitStruct.Pin = IGBT_FAULT_Pin;
  GPIO_InitStruct.Mode = GPIO_MODE_IT_RISING;
  GPIO_InitStruct.Pull = GPIO_NOPULL;
  HAL_GPIO_Init(IGBT_FAULT_GPIO_Port, &GPIO_InitStruct);

  /*Configure GPIO pins : SOFTSTART_Pin ENC_ENABLE_Pin */
  GPIO_InitStruct.Pin = SOFTSTART_Pin|ENC_ENABLE_Pin;
  GPIO_InitStruct.Mode = GPIO_MODE_OUTPUT_PP;
  GPIO_InitStruct.Pull = GPIO_NOPULL;
  GPIO_InitStruct.Speed = GPIO_SPEED_FREQ_LOW;
  HAL_GPIO_Init(GPIOC, &GPIO_InitStruct);

  /*Configure GPIO pins : ENC_SHORT_Pin ENC_Z_Pin */
  GPIO_InitStruct.Pin = ENC_SHORT_Pin|ENC_Z_Pin;
  GPIO_InitStruct.Mode = GPIO_MODE_IT_RISING;
  GPIO_InitStruct.Pull = GPIO_NOPULL;
  HAL_GPIO_Init(GPIOC, &GPIO_InitStruct);

  /*Configure GPIO pins : ADC_CS_Pin OLED_CS_Pin OLED_RESET_Pin MODBUS_DEB9_Pin */
  GPIO_InitStruct.Pin = ADC_CS_Pin|OLED_CS_Pin|OLED_RESET_Pin|MODBUS_DEB9_Pin;
  GPIO_InitStruct.Mode = GPIO_MODE_OUTPUT_PP;
  GPIO_InitStruct.Pull = GPIO_NOPULL;
  GPIO_InitStruct.Speed = GPIO_SPEED_FREQ_LOW;
  HAL_GPIO_Init(GPIOB, &GPIO_InitStruct);

  /*Configure GPIO pins : BTN_ENT_Pin BTN_UP_Pin BTN_DOWN_Pin BTN_BACK_Pin */
  GPIO_InitStruct.Pin = BTN_ENT_Pin|BTN_UP_Pin|BTN_DOWN_Pin|BTN_BACK_Pin;
  GPIO_InitStruct.Mode = GPIO_MODE_INPUT;
  GPIO_InitStruct.Pull = GPIO_PULLUP;
  HAL_GPIO_Init(GPIOD, &GPIO_InitStruct);

  /*Configure GPIO pin : DIR_IN_Pin */
  GPIO_InitStruct.Pin = DIR_IN_Pin;
  GPIO_InitStruct.Mode = GPIO_MODE_IT_RISING_FALLING;
  GPIO_InitStruct.Pull = GPIO_NOPULL;
  HAL_GPIO_Init(DIR_IN_GPIO_Port, &GPIO_InitStruct);

  /*Configure GPIO pins : LED_STATUS_Pin LED_ERROR_Pin ETH_RESET_Pin ETH_CS_Pin
                           MODBUS_DE_Pin */
  GPIO_InitStruct.Pin = LED_STATUS_Pin|LED_ERROR_Pin|ETH_RESET_Pin|ETH_CS_Pin
                          |MODBUS_DE_Pin;
  GPIO_InitStruct.Mode = GPIO_MODE_OUTPUT_PP;
  GPIO_InitStruct.Pull = GPIO_NOPULL;
  GPIO_InitStruct.Speed = GPIO_SPEED_FREQ_LOW;
  HAL_GPIO_Init(GPIOD, &GPIO_InitStruct);

  /*Configure GPIO pins : ENCODER_DE_Pin OLED_DC_Pin */
  GPIO_InitStruct.Pin = ENCODER_DE_Pin|OLED_DC_Pin;
  GPIO_InitStruct.Mode = GPIO_MODE_OUTPUT_PP;
  GPIO_InitStruct.Pull = GPIO_NOPULL;
  GPIO_InitStruct.Speed = GPIO_SPEED_FREQ_LOW;
  HAL_GPIO_Init(GPIOA, &GPIO_InitStruct);

  /*Configure GPIO pin : ETH_INT_Pin */
  GPIO_InitStruct.Pin = ETH_INT_Pin;
  GPIO_InitStruct.Mode = GPIO_MODE_IT_RISING;
  GPIO_InitStruct.Pull = GPIO_NOPULL;
  HAL_GPIO_Init(ETH_INT_GPIO_Port, &GPIO_InitStruct);

  /* EXTI interrupt init*/
  HAL_NVIC_SetPriority(EXTI1_IRQn, 5, 0);
  HAL_NVIC_EnableIRQ(EXTI1_IRQn);

  HAL_NVIC_SetPriority(EXTI9_5_IRQn, 5, 0);
  HAL_NVIC_EnableIRQ(EXTI9_5_IRQn);

  HAL_NVIC_SetPriority(EXTI15_10_IRQn, 5, 0);
  HAL_NVIC_EnableIRQ(EXTI15_10_IRQn);

}

/* USER CODE BEGIN 4 */

void _putchar(char character)
{
        ITM_SendChar(character);
}

void HAL_ADC_ConvCpltCallback(ADC_HandleTypeDef* hadc){
	//HAL_GPIO_WritePin(ETH_CS_GPIO_Port, ETH_CS_Pin, 1);
	uint16_t avg_U_samples=0;
	uint16_t avg_V_samples=0;
	//calculate zero-current voltage of current transducers to bias further readings
	if(inverter.zerocurrent_ADC_samples_U==0){
		for(uint8_t i=0;i<10;i+=2){
			avg_U_samples+=inverter.output_current_adc_buffer[i];
			avg_V_samples+=inverter.output_current_adc_buffer[i+1];
		}
		inverter.zerocurrent_ADC_samples_U=avg_U_samples/5;
		inverter.zerocurrent_ADC_samples_V=avg_V_samples/5;
	}else{ //average 5 ADC readings and calculate phase currents
		for(uint8_t i=0;i<10;i+=2){
			avg_U_samples+=inverter.output_current_adc_buffer[i];
			avg_V_samples+=inverter.output_current_adc_buffer[i+1];
		}
		//calculate phase current
		inverter.I_U=LowPassFilterA(0.0001f, 0.0000125f, -((float)avg_U_samples/5.0f-inverter.zerocurrent_ADC_samples_U)/ADC_SAMPLES_PER_AMP, &inverter.I_U);
		inverter.I_V=LowPassFilterA(0.0001f, 0.0000125f,-((float)avg_V_samples/5.0f-inverter.zerocurrent_ADC_samples_V)/ADC_SAMPLES_PER_AMP,&inverter.I_V);
		inverter.I_W=-inverter.I_U-inverter.I_V;
		//motor ovecurrent trip
		float currentlimit=parameter_set.motor_max_current*1.5f;
		if(inverter.I_U>currentlimit || inverter.I_U<(-currentlimit)){inverter_error_trip(motor_overcurrent);}
		if(inverter.I_V>currentlimit || inverter.I_V<(-currentlimit)){inverter_error_trip(motor_overcurrent);}
		if(inverter.I_W>currentlimit || inverter.I_W<(-currentlimit)){inverter_error_trip(motor_overcurrent);}
		//inverter overcurrent trip if motor limit higher than inverter limit
		if(inverter.I_U>INVERTER_OVERCURRENT_TRIP_LEVEL || inverter.I_U<(-INVERTER_OVERCURRENT_TRIP_LEVEL)){inverter_error_trip(inverter_overcurrent);}
		if(inverter.I_V>INVERTER_OVERCURRENT_TRIP_LEVEL || inverter.I_V<(-INVERTER_OVERCURRENT_TRIP_LEVEL)){inverter_error_trip(inverter_overcurrent);}
		if(inverter.I_W>INVERTER_OVERCURRENT_TRIP_LEVEL || inverter.I_W<(-INVERTER_OVERCURRENT_TRIP_LEVEL)){inverter_error_trip(inverter_overcurrent);}
	}
	//calculation takes 2us, aquisition of 5(10) samples takes 12,5us
	//HAL_GPIO_WritePin(ETH_CS_GPIO_Port, ETH_CS_Pin, 0);
}

void HAL_SPI_TxCpltCallback(SPI_HandleTypeDef * hspi){
	if(hspi->Instance==SPI1){
		HAL_GPIO_WritePin(OLED_CS_GPIO_Port, OLED_CS_Pin, 1);
	}
}
void HAL_SPI_TxRxCpltCallback(SPI_HandleTypeDef * hspi){
	if(hspi->Instance==SPI2){
		HOT_ADC_RX_Cplt();
	}
}

void HAL_GPIO_EXTI_Callback(uint16_t GPIO_Pin)
{
  if(GPIO_Pin == GPIO_PIN_13) {
	 if(((DIR_IN_GPIO_Port->IDR) & DIR_IN_Pin) != (uint32_t)GPIO_PIN_RESET){TIM4->CR1&= ~(1 << 4);} //dir input polarity is reversed
	 //HAL_GPIO_ReadPin(DIR_IN_GPIO_Port, DIR_IN_Pin);
	 else{TIM4->CR1|=1<<4;}//change STEP input timer counting direction to downcounting,
  }
}

/* USER CODE END 4 */

void StartDefaultTask(void *argument)
{
  /* init code for USB_DEVICE */
  MX_USB_DEVICE_Init();
  /* USER CODE BEGIN 5 */
	osThreadSuspend(taskModbusUSBHandle);//start usb communication task
	inverter_setup();
	osThreadResume(taskModbusUSBHandle);//start usb communication task
	osThreadResume(uiTaskHandle);
	/* Infinite loop */
	for(;;)
	{
		DCBus_voltage_check();
		osDelay(1);
	}
  /* USER CODE END 5 */
}

void StartTaskModbusUSB(void *argument)
{
  /* USER CODE BEGIN StartTaskModbusUSB */
	//
	ptrModbusUSBinstance=calloc(1,sizeof(modbus_instance_t));
	ModbusUSB_init(ptrModbusUSBinstance);
  /* Infinite loop */
  for(;;)
  {
	process_modbus_command(ptrModbusUSBinstance);
    ulTaskNotifyTake(pdTRUE, portMAX_DELAY);
  }
  /* USER CODE END StartTaskModbusUSB */
}

void uiTaskStart(void *argument)
{
  /* USER CODE BEGIN uiTaskStart */
	osTimerStart(LEDTimerHandle, 100);
	display_init();
	osThreadSuspend(uiTaskHandle);
	osDelay(2000);
	/* Infinite loop */
	for(;;)
	{
		draw();
	}
  /* USER CODE END uiTaskStart */
}

void canopen_task(void *argument)
{
  /* USER CODE BEGIN canopen_task */
	CANopenNodeSTM32 canOpenNodeSTM32;
	canOpenNodeSTM32.CANHandle = &hcan1;
	canOpenNodeSTM32.HWInitFunction = MX_CAN1_Init;
	canOpenNodeSTM32.timerHandle = &htim6;
	canOpenNodeSTM32.desiredNodeID = 2;
	canOpenNodeSTM32.baudrate = 250;
	initialize_OD_extensions(); //initialize custom read/write functions of parameter list
	canopen_app_init(&canOpenNodeSTM32);
	/* Infinite loop */
	for(;;)
	{
		canopen_app_process();
		osDelay(1);
	}
  /* USER CODE END canopen_task */
}

/* timerSoftstartCallback function */
void timerSoftstartCallback(void *argument)
{
  /* USER CODE BEGIN timerSoftstartCallback */
	if(inverter.DCbus_voltage>=inverter.undervoltage_limit+10.0f){
		HAL_GPIO_WritePin(SOFTSTART_GPIO_Port, SOFTSTART_Pin, 1);
		inverter.softstart_finished=1;
	}
  /* USER CODE END timerSoftstartCallback */
}

/* LEDTimerCallback function */
void LEDTimerCallback(void *argument)
{
  /* USER CODE BEGIN LEDTimerCallback */
	if(HAL_TIM_Base_GetState(&htim5)==HAL_TIM_STATE_BUSY){
		switch(inverter.state){
		case operation_enabled:  //status on error off
			HAL_GPIO_WritePin(LED_STATUS_GPIO_Port, LED_STATUS_Pin,1);
			HAL_GPIO_WritePin(LED_ERROR_GPIO_Port, LED_ERROR_Pin, 0);
			break;
		case switched_on: case ready_to_switch_on: case quickstop_active: //status blink error off
			HAL_GPIO_TogglePin(LED_STATUS_GPIO_Port, LED_STATUS_Pin);
			HAL_GPIO_WritePin(LED_ERROR_GPIO_Port, LED_ERROR_Pin, 0);
			break;
		case switch_on_disabled: //status off error blink
			HAL_GPIO_WritePin(LED_STATUS_GPIO_Port, LED_STATUS_Pin,0);
			HAL_GPIO_TogglePin(LED_ERROR_GPIO_Port, LED_ERROR_Pin);
			break;
		case faulted: //status off error on
			HAL_GPIO_WritePin(LED_STATUS_GPIO_Port, LED_STATUS_Pin,0);
			HAL_GPIO_WritePin(LED_ERROR_GPIO_Port, LED_ERROR_Pin, 1);
			break;
		default: //both on
			HAL_GPIO_WritePin(LED_STATUS_GPIO_Port, LED_STATUS_Pin, 1);
			HAL_GPIO_WritePin(LED_ERROR_GPIO_Port, LED_ERROR_Pin, 1);
			break;
		}
	}else{
		//both on if motor control loop is not working
		HAL_GPIO_WritePin(LED_STATUS_GPIO_Port, LED_STATUS_Pin, 1);
		HAL_GPIO_WritePin(LED_ERROR_GPIO_Port, LED_ERROR_Pin, 1);
	}
  /* USER CODE END LEDTimerCallback */
}

void HAL_TIM_PeriodElapsedCallback(TIM_HandleTypeDef *htim)
{
  if (htim->Instance == TIM11) {
    HAL_IncTick();
  }
  /* USER CODE BEGIN Callback 1 */
  if(htim->Instance == TIM6) {
	  canopen_app_interrupt();
  }
  if(htim->Instance == TIM7) {
	  if((parameter_set.motor_feedback_type==mitsubishi_encoder) && (mitsubishi_encoder_data.encoder_state!=encoder_error_no_communication || mitsubishi_encoder_data.encoder_state!=encoder_error_cheksum )){
	  		mitsubishi_encoder_send_command();
	  	}
	  if(parameter_set.motor_feedback_type==delta_encoder){delta_encoder_read_position();}
	  if(parameter_set.motor_feedback_type==omron_omnucg_encoder){omnucg_encoder_read_position();}

    }
  /* USER CODE END Callback 1 */
}

void Error_Handler(void)
{
  __disable_irq();
  while (1)
  {
  }
}

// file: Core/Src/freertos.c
/* USER CODE BEGIN Header */
/**
  ******************************************************************************
  * File Name          : freertos.c
  * Description        : Code for freertos applications
  ******************************************************************************
  * @attention
  *
  * Copyright (c) 2023 STMicroelectronics.
  * All rights reserved.
  *
  * This software is licensed under terms that can be found in the LICENSE file
  * in the root directory of this software component.
  * If no LICENSE file comes with this software, it is provided AS-IS.
  *
  ******************************************************************************
  */
/* USER CODE END Header */

#include "FreeRTOS.h"
#include "task.h"
#include "main.h"

/* USER CODE BEGIN Includes */
#include "printf.h"
/* USER CODE END Includes */

/* Hook prototypes */
void configureTimerForRunTimeStats(void);
unsigned long getRunTimeCounterValue(void);
void vApplicationStackOverflowHook(xTaskHandle xTask, signed char *pcTaskName);
void vApplicationMallocFailedHook(void);

/* USER CODE BEGIN 1 */
/* Functions needed when configGENERATE_RUN_TIME_STATS is on */
__weak void configureTimerForRunTimeStats(void)
{

}

__weak unsigned long getRunTimeCounterValue(void)
{
return 0;
}
/* USER CODE END 1 */

/* USER CODE BEGIN 4 */
void vApplicationStackOverflowHook(xTaskHandle xTask, signed char *pcTaskName)
{
   /* Run time stack overflow checking is performed if
   configCHECK_FOR_STACK_OVERFLOW is defined to 1 or 2. This hook function is
   called if a stack overflow is detected. */
	printf("Stack overflow");
}
/* USER CODE END 4 */

/* USER CODE BEGIN 5 */
void vApplicationMallocFailedHook(void)
{
   /* vApplicationMallocFailedHook() will only be called if
   configUSE_MALLOC_FAILED_HOOK is set to 1 in FreeRTOSConfig.h. It is a hook
   function that will get called if a call to pvPortMalloc() fails.
   pvPortMalloc() is called internally by the kernel whenever a task, queue,
   timer or semaphore is created. It is also called by various parts of the
   demo application. If heap_1.c or heap_2.c are used, then the size of the
   heap available to pvPortMalloc() is defined by configTOTAL_HEAP_SIZE in
   FreeRTOSConfig.h, and the xPortGetFreeHeapSize() API function can be used
   to query the size of free heap space that remains (although it does not
   provide information on how the remaining heap might be fragmented). */
	printf("Malloc fail");
}
/* USER CODE END 5 */
